# ARMv8M-Extended register map
Registers are read-only, no defined reset value unless marked. A register's access mark holds for its fields unless they carry their own. Offsets are from the block's base; [hi:lo] are bit positions; {n}, {i} and the like mark numbered series.

## EWIC_CoreSight — External Wakeup Interrupt Controller CoreSight registers
Base 0xE0047F00
0x00 EWIC_ITCTRL — EWIC Integration Mode Control Register used to dynamically switch between functional mode and integration mode. The EWIC does not support integration mode, and this register is RAZ.
0xA0 EWIC_CLAIMSET rw — EWIC Claim Tag Set Register the EWIC_CLAIMSET register is used to set whether functionality is in use by a debug agent. The EWIC does not have any associated debug functionality, and this register is 0xF.
0xA4 EWIC_CLAIMCLR rw — EWIC Claim Tag Clear Register the EWIC_CLAIMCLR register is used to set whether functionality is in use by a debug agent. The EWIC does not have any associated debug functionality, and this register is 0x0.
0xA8 EWIC_DEVAFF0 — EWIC Device Affinity Register 0 the EWIC_DEVAFF0 register enables a debugger to determine whether the EWIC and the processor have an affinity with each other. The EWIC does not have any associated debug functionality, and this register is 0x80000000.
0xAC EWIC_DEVAFF1 — EWIC Device Affinity Register 1 the EWIC_DEVAFF1 register enables a debugger to determine whether the EWIC and the processor have an affinity with each other. The EWIC does not have any associated debug functionality, and this register is 0x0.
0xB0 EWIC_LAR wo — EWIC Software Lock Access Register the EWIC_LAR register controls software access to CoreSight components to reduce the likelihood of accidental access to the EWIC. The EWIC does not support software locking, and writing to this register has no affect.
0xB4 EWIC_LSR — EWIC Software Lock Status Register the EWIC_LSR register controls software access to CoreSight components to reduce the likelihood of accidental access to the EWIC. The EWIC does not support software locking, and this register is RAZ.
0xB8 EWIC_AUTHSTATUS — EWIC Authentication Status Register the EWIC_AUTHSTATUS register indicates whether the EWIC includes debug functionality. The EWIC is not a debug component, therefore, the EWIC_AUTHSTATIS register is RAZ.
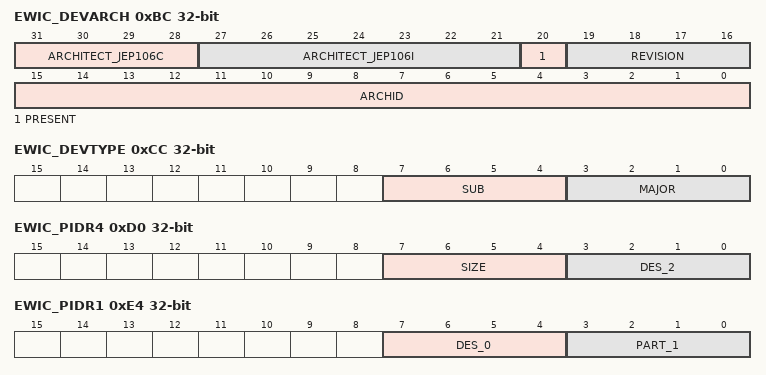
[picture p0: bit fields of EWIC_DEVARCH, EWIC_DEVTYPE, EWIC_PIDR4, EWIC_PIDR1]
0xBC EWIC_DEVARCH — EWIC Device Architecture Register identifies the architecture of the EWIC
  [31:28] ARCHITECT_JEP106C — Defines the architect of the component, JEP106 continuation code
  [27:21] ARCHITECT_JEP106I — Defines the architect of the component, JEP106 identification code
  [20] PRESENT — Indicates the presence of this register. This value is 0b1.
  [19:16] REVISION — Architecture revision. This value is 0b0000.
  [15:0] ARCHID — Returns a value that identifies the architecture of the component. This value is 0x0A07 corresponding to EWIC architecture.
0xC0 EWIC_DEVID2 — EWIC Device Configuration Register 2 the EWIC_DEVID2 indicates some capabilities of the EWIC. This register is RAZ/WI.
0xC4 EWIC_DEVID1 — EWIC Device Configuration Register 1 the EWIC_DEVID1 indicates some capabilities of the EWIC. This register is RAZ/WI.
0xC8 EWIC_DEVID — EWIC Device Configuration Register the EWIC_DEVID indicates some capabilities of the EWIC. This register is RAZ/WI.
0xCC EWIC_DEVTYPE — EWIC Device Type Identifier Register, EWIC_DEVTYPE provides part number information about the EWIC component to the debugger.
  [7:4] SUB — Sub type for the component device type. This field is set to 0b0000.
  [3:0] MAJOR — Major type for the component device type. This field is set to 0b0000.
0xD0 EWIC_PIDR4 — Peripheral Identification Register 4 provides information about the memory size and JEP106 continuation code that the External Wakeup Interrupt Controller (EWIC) component uses
  [7:4] SIZE — This field indicates the memory size that the EWIC uses. This field returns 0x0 indicating that the component uses an UNKNOWN number of 4KB blocks.
  [3:0] DES_2 — JEP106 continuation code. Together with EWIC_PIDR2.DES_1 and EWIC_PIDR1.DES_0, they indicate the designer of the component, not the implementer, except where the two are the same. The reset value of this field is 0x4.
{0xC0+4i} EWIC_PIDR{i} (i=5..7) — Peripheral Identification Register {i} the register is reserved, RES0
0xE0 EWIC_PIDR0 — Peripheral Identification Register 0 indicates the EWIC component part number
  [7:0] PART_0 — This field indicates the part number. When taken together with EWIC_PIDR1.PART_1, it indicates the component. The part number is selected by the designer of the component.
0xE4 EWIC_PIDR1 — Peripheral Identification Register 1 indicates the EWIC component JEP106 continuation code and part number
  [7:4] DES_0 — This field indicates the JEP106 identification code, bits[3:0]. Together, with EWIC_PIDR4.DES_2 and EWIC_PIDR2.DES_1, they indicate the designer of the component and not the implementer, except where the two are the same. The reset value is 0xB.
  [3:0] PART_1 — This field indicates the part number, bits[11:8]. Taken together with EWIC_PIDR0.PART_0 it indicates the component. The part number is selected by the designer of the component. The reset value is 0xD.
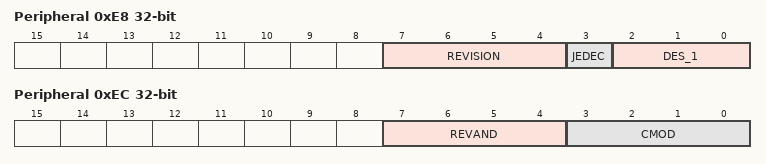
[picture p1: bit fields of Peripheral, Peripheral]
0xE8 Peripheral Identification Register 2 — Indicates the EWIC component revision number, JEDEC value, and part of the JEP106 continuation code
  [7:4] REVISION — This field indicates the revision number of the EWIC component. It is an incremental value starting at 0x0 for the first design. The reset value is 0x0.
  [3] JEDEC — This field is always 1, indicating that a JEDEC assigned value is used.
  [2:0] DES_1 — This field is the JEP106 identification code, bits[6:4]. Together, with CTI_PIDR4.DES_2 and CTI_PIDR1.DES_0, they indicate the designer of the component and not the implementer, except where the two are the same. The reset value is 0b011.
0xEC Peripheral Identification Register 3 — Indicates minor errata fixes of the Cross Trigger Interface (CTI) component and if you have modified the behavior of the component
  [7:4] REVAND — This field indicates minor errata fixes specific to this design, for example metal fixes after implementation. In most cases this field is 0x0.
  [3:0] CMOD — Customer modified. Where the component is reusable IP, this value indicates whether you have modified the behavior of the component. In most cases, this field is 0x0.
0xF0 EWIC_CIDR0 — Component Identification Register 0 indicates the preamble
  [7:0] PRMBL_0 — Preamble. This field returns 0x0D.
0xF4 EWIC_CIDR1 — Component Identification Register 1 indicates the component class and preamble
  [7:0] CLASS — Component class. Returns 0x9, indicating this is a CoreSight component.
  [7:0] PRMBL_1 — Preamble. This field returns 0x0.
0xF8 EWIC_CIDR2 — Component Identification Register 2 indicates the preamble
  [7:0] PRMBL_2 — Preamble. This field returns 0x05.
0xFC EWIC_CIDR3 — Component Identification Register 3 indicates the preamble
  [7:0] PRMBL_3 — Preamble. This field returns 0xB1.
